AUTOSAR XML (schema 4.0)
package /Battery_EV_Components
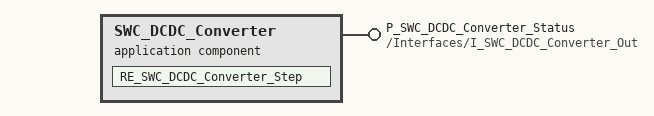
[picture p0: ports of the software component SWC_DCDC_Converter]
  application sw component type SWC_DCDC_Converter  # AUTOSAR Application SWC SWC_DCDC_Converter for Battery EV Safety
    provide port P_SWC_DCDC_Converter_Status: provided-interface=/Interfaces/I_SWC_DCDC_Converter_Out
    behavior SWC_DCDC_Converter_Behavior
      runnable RE_SWC_DCDC_Converter_Step: symbol=SWC_DCDC_Converter_Step
  sender receiver interface I_SWC_DCDC_Converter_Out
    data DE_SWC_DCDC_Converter_Health: type=/AUTOSAR/Platform/uint32
